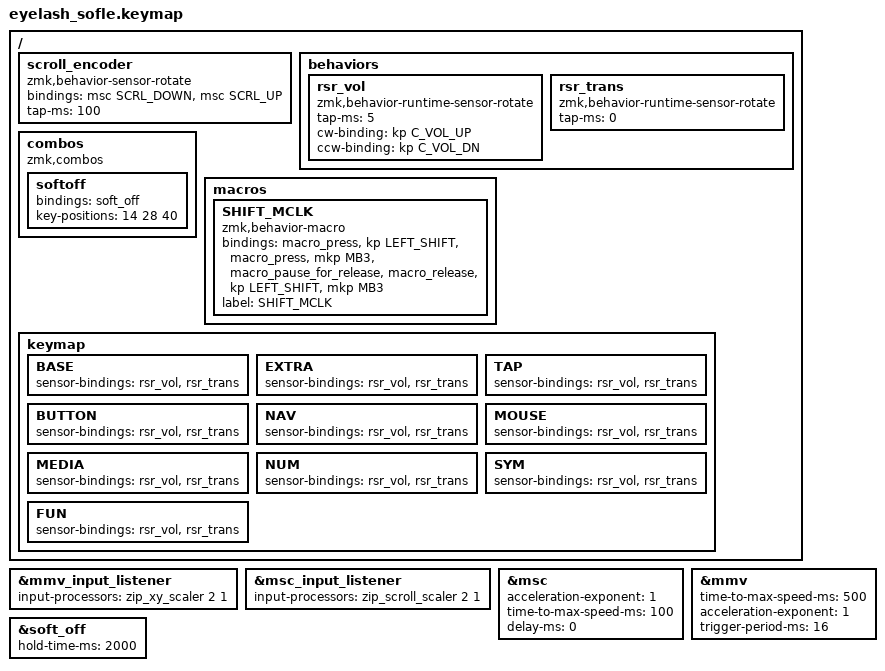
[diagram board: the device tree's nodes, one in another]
// Copyright 2024
// SPDX-License-Identifier: MIT
//
// Miryoku layout on the Eyelash Sofle (QWERTY variant).
//
// Miryoku is an ergonomic, minimal, orthogonal, and universal keyboard layout.
// See https://github.com/manna-harbour/miryoku/ for the full reference.
//
// Layer summary:
//   0 BASE   - QWERTY alphas with home-row mods and layer-tap thumbs
//   1 EXTRA  - Alternate base (defaults to QWERTY when MIRYOKU_ALPHAS=QWERTY)
//   2 TAP    - Base without any hold-tap behaviour (plain typing)
//   3 BUTTON - Mouse buttons, mods, and clipboard on both hands
//   4 NAV    - Cursor keys, editing, and clipboard (right hand)
//   5 MOUSE  - Mouse movement and scroll wheel (right hand)
//   6 MEDIA  - Media, RGB, and Bluetooth controls (right hand)
//   7 NUM    - Numerals and symbols (left hand)
//   8 SYM    - Shifted symbols (left hand)
//   9 FUN    - Function keys and system keys (left hand)

// ---------------------------------------------------------------------------
// Miryoku options -- set BEFORE including the Miryoku headers.
// See miryoku_zmk documentation for the full list.
// ---------------------------------------------------------------------------

#define MIRYOKU_ALPHAS_QWERTY                       // base alphas
#define MIRYOKU_KLUDGE_SOFT_OFF                     // top-outer-pinkie key -> soft-off (this board has soft-off configured)
#define MIRYOKU_KLUDGE_GLOBALSHIFTFUNCTIONS         // enable shift-morph for RGB / EXT_POWER

// ---------------------------------------------------------------------------
// Standard ZMK includes.
// ---------------------------------------------------------------------------

#include <input/processors.dtsi>
#include <zephyr/dt-bindings/input/input-event-codes.h>
#include <behaviors.dtsi>
#include <behaviors/runtime-sensor-rotate.dtsi>
#include <dt-bindings/zmk/bt.h>
#include <dt-bindings/zmk/keys.h>
#include <dt-bindings/zmk/outputs.h>
#include <dt-bindings/zmk/pointing.h>
#include <dt-bindings/zmk/rgb.h>

// ---------------------------------------------------------------------------
// Miryoku core: mapping + layer definitions.
// ---------------------------------------------------------------------------

#include "miryoku/mapping/eyelash_sofle.h"
#include "miryoku/miryoku.dtsi"

// ---------------------------------------------------------------------------
// Eyelash Sofle hardware tuning (encoder, pointer acceleration, soft-off
// hold time, and extra behaviours/combos). These live alongside the Miryoku
// layers rather than inside them so they apply on every layer.
// ---------------------------------------------------------------------------

&mmv_input_listener { input-processors = <&zip_xy_scaler 2 1>; };

&msc_input_listener { input-processors = <&zip_scroll_scaler 2 1>; };

&msc {
    acceleration-exponent = <1>;
    time-to-max-speed-ms = <100>;
    delay-ms = <0>;
};

&mmv {
    time-to-max-speed-ms = <500>;
    acceleration-exponent = <1>;
    trigger-period-ms = <16>;
};

&soft_off { hold-time-ms = <2000>; };

/ {
    scroll_encoder: scroll_encoder {
        compatible = "zmk,behavior-sensor-rotate";
        #sensor-binding-cells = <0>;
        bindings = <&msc SCRL_DOWN>, <&msc SCRL_UP>;
        tap-ms = <100>;
    };

    behaviors {
        // Left encoder rotation: volume up/down on every layer.
        rsr_vol: rsr_vol {
            compatible = "zmk,behavior-runtime-sensor-rotate";
            #sensor-binding-cells = <0>;
            tap-ms = <5>;
            cw-binding = <&kp C_VOL_UP>;
            ccw-binding = <&kp C_VOL_DN>;
        };

        // Placeholder for the right sensor -- no rotation action by default.
        rsr_trans: rsr_trans {
            compatible = "zmk,behavior-runtime-sensor-rotate";
            #sensor-binding-cells = <0>;
            tap-ms = <0>;
        };
    };

    combos {
        compatible = "zmk,combos";

        // Hold Q + S + Z (left-hand top / home / bottom pinkie column) to
        // shut the keyboard down. Positions (0-indexed in the 64-key layout)
        // 14, 28, 40 -- matches the softoff combo from the original keymap.
        softoff {
            bindings = <&soft_off>;
            key-positions = <14 28 40>;
        };
    };

    macros {
        // Preserved from the original keymap: shift + middle-click chord.
        SHIFT_MCLK: SHIFT_MCLK {
            compatible = "zmk,behavior-macro";
            #binding-cells = <0>;
            bindings
                = <&macro_press>
                , <&kp LEFT_SHIFT>
                , <&macro_press>
                , <&mkp MB3>
                , <&macro_pause_for_release>
                , <&macro_release>
                , <&kp LEFT_SHIFT &mkp MB3>
                ;
            label = "SHIFT_MCLK";
        };
    };
};

// ---------------------------------------------------------------------------
// Encoder sensor bindings per layer.
//
// Miryoku's miryoku.dtsi generates the ten layer nodes for us but does not
// set any sensor bindings, so we extend each layer here (device tree merges
// nodes with matching paths). `rsr_vol` handles the left encoder (volume
// up/down) and `rsr_trans` is a no-op placeholder for the right encoder.
// ---------------------------------------------------------------------------

/ {
    keymap {
        BASE   { sensor-bindings = <&rsr_vol &rsr_trans>; };
        EXTRA  { sensor-bindings = <&rsr_vol &rsr_trans>; };
        TAP    { sensor-bindings = <&rsr_vol &rsr_trans>; };
        BUTTON { sensor-bindings = <&rsr_vol &rsr_trans>; };
        NAV    { sensor-bindings = <&rsr_vol &rsr_trans>; };
        MOUSE  { sensor-bindings = <&rsr_vol &rsr_trans>; };
        MEDIA  { sensor-bindings = <&rsr_vol &rsr_trans>; };
        NUM    { sensor-bindings = <&rsr_vol &rsr_trans>; };
        SYM    { sensor-bindings = <&rsr_vol &rsr_trans>; };
        FUN    { sensor-bindings = <&rsr_vol &rsr_trans>; };
    };
};
